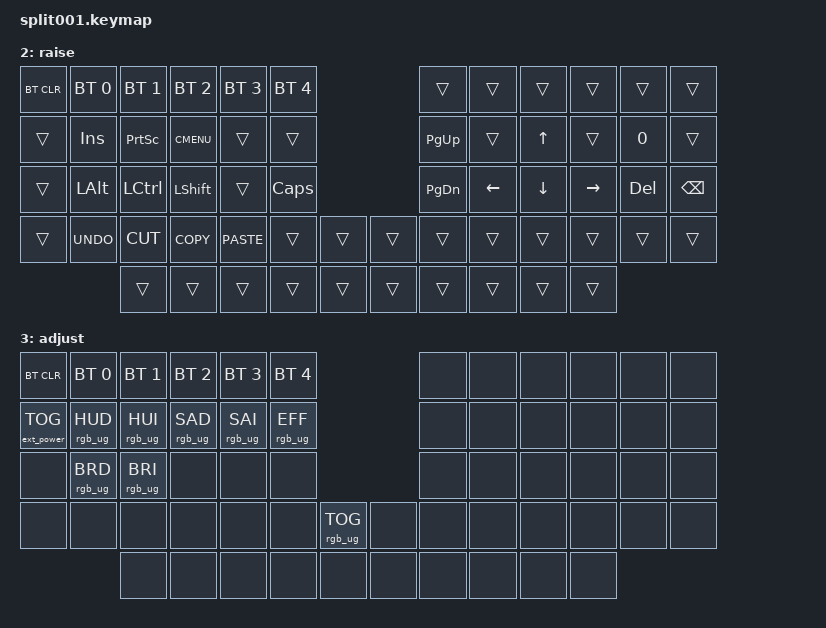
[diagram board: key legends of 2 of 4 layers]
/*
 * Copyright (c) 2020 The ZMK Contributors
 *
 * SPDX-License-Identifier: MIT
 */

#include <behaviors.dtsi>
#include <dt-bindings/zmk/keys.h>
#include <dt-bindings/zmk/bt.h>
#include <dt-bindings/zmk/rgb.h>
#include <dt-bindings/zmk/ext_power.h>

#define BASE 0
#define LOWER 1
#define RAISE 2
#define ADJUST 3

/ {

   // Activate ADJUST layer by pressing raise and lower
    conditional_layers {
        compatible = "zmk,conditional-layers";
        adjust_layer {
            if-layers = <LOWER RAISE>;
            then-layer = <ADJUST>;
        };
    };

    keymap {
        compatible = "zmk,keymap";

        default_layer {
            display-name = "default";
            //    RC(0,0) RC(0,1) RC(0,2) RC(0,3)         RC(0,4) RC(0,5) RC(0,6) RC(0,7) RC(0,8) RC(0,9)                          RC(0,12) RC(0,13) RC(0,14) RC(0,15) RC(0,16) RC(0,17)      RC(0,18) RC(0,19) RC(0,20) RC(0,21)
            //    RC(1,0) RC(1,1) RC(1,2) RC(1,3)         RC(1,4) RC(1,5) RC(1,6) RC(1,7) RC(1,8) RC(1,9) RC(1,10)        RC(1,11) RC(1,12) RC(1,13) RC(1,14) RC(1,15) RC(1,16) RC(1,17)      RC(1,18) RC(1,19) RC(1,20) RC(1,21)
            //    RC(2,0) RC(2,1) RC(2,2) RC(2,3)         RC(2,4) RC(2,5) RC(2,6) RC(2,7) RC(2,8) RC(2,9) RC(2,10)        RC(2,11) RC(2,12) RC(2,13) RC(2,14) RC(2,15) RC(2,16) RC(2,17)      RC(2,18) RC(2,19) RC(2,20) RC(2,21)
            //    RC(3,0) RC(3,1) RC(3,2) RC(3,3)         RC(3,4) RC(3,5) RC(3,6) RC(3,7) RC(3,8) RC(3,9) RC(3,10)        RC(3,11) RC(3,12) RC(3,13) RC(3,14) RC(3,15) RC(3,16) RC(3,17)      RC(3,18) RC(3,19) RC(3,20) RC(3,21) 
            //                                                    RC(4,5) RC(4,6) RC(4,7) RC(4,8) RC(4,9) RC(4,10)        RC(4,11) RC(4,12) RC(4,13) RC(4,14) RC(4,15) RC(4,16)

            // ------------------------------------------------------------------------------------------------------------
            // |   `   |  1  |  2  |  3   |  4   |  5   |                   |  6   |  7    |  8    |  9   |   0   |       |
            // |  ESC  |  Q  |  W  |  E   |  R   |  T   |                   |  Y   |  U    |  I    |  O   |   P   | BKSPC |
            // |  TAB  |  A  |  S  |  D   |  F   |  G   |                   |  H   |  J    |  K    |  L   |   ;   |   '   |
            // | SHIFT |  Z  |  X  |  C   |  V   |  B   |  MUTE  |  |       |  N   |  M    |  ,    |  .   |   /   | SHIFT |
            //               | GUI | ALT  | CTRL | LOWER|  ENTER |  | SPACE | RAISE| CTRL  | ALT   | GUI  |
                        bindings = <
        /*  0        1      2         3        ||  4         5        6        7         8          9        10        ||  11        12        13       14        15      16       17       ||  18       19     20        21      */            
            &kp N7   &kp N8 &kp N9    &kp DEL      &kp ESC   &kp N1   &kp N2   &kp N3    &kp N4    &kp N5                            &kp N6    &kp N7   &kp N8    &kp N9  &kp N0   &none        &kp N7   &kp N8 &kp N9    &kp DEL  
            &kp N4   &kp N5 &kp N6    &kp ASTRK    &kp TAB   &kp Q    &kp W    &kp E     &kp R     &kp T     &kp C_MUTE    &none     &kp Y     &kp U    &kp I     &kp O   &kp P    &kp BSPC     &kp N4   &kp N5 &kp N6    &kp ASTRK
            &kp N1   &kp N2 &kp N3    &kp FLSH     &kp LSHFT &kp A    &kp S    &kp D     &kp F     &kp G     &none         &none     &kp H     &kp J    &kp K     &kp L   &kp SEMI &kp SQT      &kp N1   &kp N2 &kp N3    &kp FLSH
            &kp PLUS &kp N0 &kp MINUS &kp EQUAL    &kp CTRL  &kp Z    &kp X    &kp C     &kp V     &kp B     &none         &none     &kp N     &kp M    &kp COMMA &kp DOT &kp FSLH &kp RSHFT    &kp PLUS &kp N0 &kp MINUS &kp EQUAL
                                                             &kp LGUI &kp LALT &kp LCTRL &mo LOWER &kp SPACE &kp RET       &mo RAISE &kp RCTRL &kp RALT &kp RGUI
                        >;

                        sensor-bindings = <&inc_dec_kp C_VOL_UP C_VOL_DN &inc_dec_kp PG_UP PG_DN>;
                    };

                    lower_layer {
                        display-name = "lower";
            // TODO: Some binds are waiting for shifted keycode support.
            // ------------------------------------------------------------------------------------------------------------
            // |       |  F1 |  F2 |  F3  |  F4  |  F5  |                   |  F6  |  F7   |  F8   |  F9  |  F10  |  F11  |
            // |   `   |  1  |  2  |  3   |  4   |  5   |                   |  6   |  7    |  8    |  9   |   0   |  F12  |
            // |       |  !  |  @  |  #   |  $   |  %   |                   |  ^   |  &    |  *    |  (   |   )   |   |   |
            // |       |  =  |  -  |  +   |  {   |  }   |        |  |       |  [   |  ]    |  ;    |  :   |   \   |       |
            //               |     |      |      |      |        |  |       |      |       |       |      |
                        bindings = <
            /*  0        1      2         3        ||  4         5           6          7            8            9            10        ||  11        12        13       14        15      16       17       ||  18       19     20        21      */            
                &kp N7   &kp N8 &kp N9    &kp DEL      &trans    &kp F1      &kp F2     &kp F3       &kp F4   &kp F5                    &kp F6    &kp F7   &kp F8    &kp F9    &kp F10   &kp F11
                &kp N4   &kp N5 &kp N6    &kp ASTRK    &kp GRAVE &kp N1      &kp N2     &kp N3       &kp N4   &kp N5                    &kp N6    &kp N7   &kp N8    &kp N9    &kp N0    &kp F12
                &kp N1   &kp N2 &kp N3    &kp FLSH     &trans    &kp EXCL    &kp AT     &kp HASH     &kp DLLR &kp PRCNT                 &kp CARET &kp AMPS &kp ASTRK &kp LPAR  &kp RPAR  &kp PIPE
                &kp PLUS &kp N0 &kp MINUS &kp EQUAL    &trans    &kp EQUAL   &kp MINUS  &kp PLUS     &kp LBRC &kp RBRC     &trans  &trans  &kp LBKT  &kp RBKT &kp SEMI  &kp COLON &kp BSLH  &trans
                                                                 &bootloader &bt BT_CLR &bt BT_SEL 0 &trans   &bt BT_SEL 1 &trans  &trans    &trans   &trans    &trans
                        >;

                        sensor-bindings = <&inc_dec_kp C_VOL_UP C_VOL_DN &inc_dec_kp PG_UP PG_DN>;
                    };

                    raise_layer {
                        display-name = "raise";
            // ------------------------------------------------------------------------------------------------------------
            // | BTCLR | BT1  | BT2  |  BT3  |  BT4  |  BT5 |                |      |      |       |      |       |       |
            // |       | INS  | PSCR | GUI   |       |      |                | PGUP |      |   ^   |      |       |       |
            // |       | ALT  | CTRL | SHIFT |       | CAPS |                | PGDN |   <- |   v   |  ->  |  DEL  | BKSPC |
            // |       | UNDO | CUT  | COPY  | PASTE |      |      |  |      |      |      |       |      |       |       |
            //                |      |       |       |      |      |  |      |      |      |       |      |
                        bindings = <
            &bt BT_CLR &bt BT_SEL 0 &bt BT_SEL 1 &bt BT_SEL 2 &bt BT_SEL 3 &bt BT_SEL 4                  &trans    &trans    &trans   &trans    &trans  &trans
            &trans     &kp INS      &kp PSCRN    &kp K_CMENU  &trans       &trans                        &kp PG_UP &trans    &kp UP   &trans    &kp N0  &trans
            &trans     &kp LALT     &kp LCTRL    &kp LSHFT    &trans       &kp CLCK                      &kp PG_DN &kp LEFT  &kp DOWN &kp RIGHT &kp DEL &kp BSPC
            &trans     &kp K_UNDO   &kp K_CUT    &kp K_COPY   &kp K_PASTE  &trans        &trans  &trans  &trans    &trans    &trans   &trans    &trans  &trans
                                    &trans       &trans       &trans       &trans        &trans  &trans  &trans    &trans    &trans   &trans
                        >;

                        sensor-bindings = <&inc_dec_kp C_VOL_UP C_VOL_DN &inc_dec_kp PG_UP PG_DN>;
                    };

                    adjust_layer {
            // ----------------------------------------------------------------------------------------------------------------------------
            // | BTCLR  |  BT1    |  BT2    |   BT3   |   BT4   |   BT5   |                  |      |      |       |      |       |       |
            // | EXTPWR | RGB_HUD | RGB_HUI | RGB_SAD | RGB_SAI | RGB_EFF |                  |      |      |       |      |       |       |
            // |        | RGB_BRD | RGB_BRI |         |         |         |                  |      |      |       |      |       |       |
            // |        |         |         |         |         |         | RGB_TOG | |      |      |      |       |      |       |       |
            //                    |         |         |         |         |         | |      |      |      |       |      |
                        display-name = "adjust";
                        bindings = <
            &bt BT_CLR        &bt BT_SEL 0    &bt BT_SEL 1    &bt BT_SEL 2    &bt BT_SEL 3    &bt BT_SEL 4                            &none &none &none &none &none &none
            &ext_power EP_TOG &rgb_ug RGB_HUD &rgb_ug RGB_HUI &rgb_ug RGB_SAD &rgb_ug RGB_SAI &rgb_ug RGB_EFF                         &none &none &none &none &none &none
            &none             &rgb_ug RGB_BRD &rgb_ug RGB_BRI &none           &none           &none                                   &none &none &none &none &none &none
            &none             &none           &none           &none           &none           &none            &rgb_ug RGB_TOG &none  &none &none &none &none &none &none
                                            &none           &none           &none           &none            &none           &none  &none &none &none &none
            >;
        };

    };
};
